# A64 register map
Vendor: Allwinner; Series: A64; File version: 0.1
CPU: CA53 0, little endian, MPU, no FPU, 0 interrupt priority bits
Registers are 32-bit, read-write, reset 0x0 unless marked. A register's access mark holds for its fields unless they carry their own. Offsets are from the block's base; lines under a group give offsets from that group; [hi:lo] are bit positions; {n}, {i} and the like mark numbered series; 'fields as' and 'values as' point back to an identical list; <NAME> marks a mode.

## Memory map
0x01700C00 CPUCFG
0x01C00000 System_Control
0x01C02000 DMA
0x01C03000 NDFC
0x01C06000 TSC
0x01C0C000 TCON0
0x01C0D000 TCON1
0x01C0F000 SMHC0
0x01C10000 SMHC1
0x01C11000 SMHC2
0x01C15000 CE_NS
0x01C15800 CE_S
0x01C17000 MSGBOX
0x01C18000 SPINLOCK
0x01C1B000 USB_HCI1
0x01C1E000 SMC
0x01C20000 CCU
0x01C20800 PIO
0x01C20C00 TIMER
0x01C21000 OWA
0x01C21400 PWM
0x01C21800 KEYADC
0x01C22000 I2S/PCM_0
0x01C22400 I2S/PCM_1
0x01C22800 I2S/PCM_2
0x01C22C00 AC
0x01C23400 SPC
0x01C25000 Thermal_Sensor
0x01C28000 UART0
0x01C28400 UART1
0x01C28800 UART2
0x01C28C00 UART3
0x01C29000 UART4
0x01C2AC00 TWI0
0x01C2B000 TWI1
0x01C2B400 TWI2
0x01C2C400 SCR
0x01C30000 EMAC
0x01C60000 High_Speed_Timer
0x01C68000 SPI0
0x01C69000 SPI1
0x01CB0000 CSI0
0x01F00000 RTC
0x01F01800 TWD
0x01F02000 CIR
0x01F02400 R_TWI
0x01F02800 R-UART
0x01F02C00 PIO

## CE_NS
Base 0x01C15000
Same registers: CE_S 0x01C15800
0x00 CE_TDQ — Task Descriptor Queue Address
  [31:0] TASK_DESCRIPTOR_QUEUE_ADDRESS
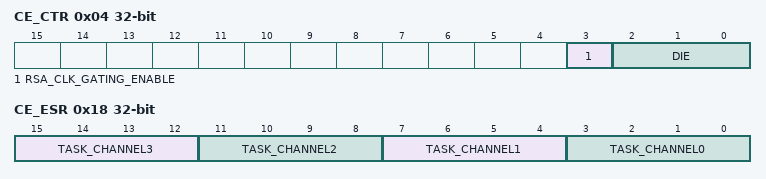
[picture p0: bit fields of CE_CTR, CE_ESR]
0x04 CE_CTR (reset mask 0x8) — Gating Control Register
  [3] RSA_CLK_GATING_ENABLE — RSA_CLK_Gating_Enable(read only for NS world) 0: RSA clk gating enable 1: RSA clk gating disable
    0=RSA_clk_gating_enable; 1=RSA_clk_gating_disable
  [2:0] DIE ro — Die Bonding ID
0x08 CE_ICR — Interrupt Control Register
  [3:0] TASK — Task chaining0-3_interrupt_enable 0: interrupt disable 1: interrupt enable
0x0C CE_ISR — Interrupt Status Register
  [3:0] TASK — Task chaining0-3_End_Pending 0: busy 1: task end It indicates that the processing of encrypt /signing or decrypt/verification has been completed . Notes: Write `1` to clear it.
0x10 CE_TLR — Task Load Register
  [0] TASK_LOAD — When set , SS starts to load the configure of task from task descriptor queue and start to perform the task if task FIFO is not full.
0x14 CE_TSR — Task Status Register
  [1:0] CURRENT ro — Current task in run 0: task chaining0 1: task chaining1 2: task chaining2 3: task chaining3
    2=task_chaining2; 3=task_chaining3
0x18 CE_ESR — Task Error type Register
  [15:12] TASK_CHANNEL3 ro — Task channel3 error type xxx1: algorithm not support xx1x: data length error x1xx: keysram access error for AES. Write `1` to clear. 1xxx: reserved
    1=algorithm not support; 2=data length error; 4=keysram access error for AES. Write `1` to clear.
  [11:8] TASK_CHANNEL2 ro — Task channel2 error type xxx1: algorithm not support xx1x: data length error x1xx: keysram access error for AES. Write `1` to clear. 1xxx: reserved
    values as TASK_CHANNEL3
  [7:4] TASK_CHANNEL1 ro — Task channel1 error type xxx1: algorithm not support xx1x: data length error x1xx: keysram access error for AES. Write `1` to clear. 1xxx: reserved
    values as TASK_CHANNEL3
  [3:0] TASK_CHANNEL0 ro — Task channel0 error type xxxlgorithm not support xx1x: data length error x1xx: keysram access error for AES. Write `1` to clear. 1xxx: reserved
    2=data length error; 4=keysram access error for AES. Write `1` to clear.
0x24 CE_CSAR — Current Source Address Register
  [31:0] CURRENT ro — Current source address of the executing task
0x28 CE_CDAR — Current Destination Address Register
  [31:0] CURRENT ro — Current destination address of the executing task
0x2C CE_TPR — Throughput Register
  [31:0] IT_INDICATES_THE_THROUGHPUT — It indicates the throughput of data from the whole processing. Notes: Write `0` to clear it.

## System_Control
Base 0x01C00000
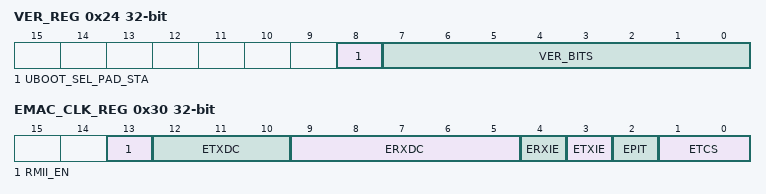
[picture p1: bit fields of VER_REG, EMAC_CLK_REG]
0x24 VER_REG (reset mask 0xFF) — Version Register
  [8] UBOOT_SEL_PAD_STA ro — U_boot Select Pin Status. 0: U_Boot; 1: Normal Boot.
    0=U_Boot; 1=Normal Boot
  [7:0] VER_BITS ro — This read-only bit field always reads back the mask revision level of the chip.
0x30 EMAC_CLK_REG — EMAC Clock Register
  [13] RMII_EN — 0 : Disable RMII Module 1 : Enable RMII Module When this bit assert, MII or RGMII interface is disabled( This means bit13 is prior to bit2)
  [12:10] ETXDC — Configure EMAC Transmit Clock Delay Chain.
  [9:5] ERXDC — Configure EMAC Receive Clock Delay Chain.
  [4] ERXIE — Enable EMAC Receive Clock Invertor. 0: Disable 1: Enable
    0=Disable; 1=Enable
  [3] ETXIE — Enable EMAC Transmit Clock Invertor. 0: Disable 1: Enable
    0=Disable; 1=Enable
  [2] EPIT — EMAC PHY Interface Type 0: MII 1: RGMII
    0=MII; 1=RGMII
  [1:0] ETCS — EMAC Transmit Clock Source 00: Transmit clock source for MII 01: External transmit clock source for GMII and RGMII 10: Internal transmit clock source for GMII and RGMII 11: Reserved
    0=Transmit clock source for MII; 1=External transmit clock source for GMII and RGMII; 2=Internal transmit clock source for GMII and RGMII

## Licence text in the file
questionable
